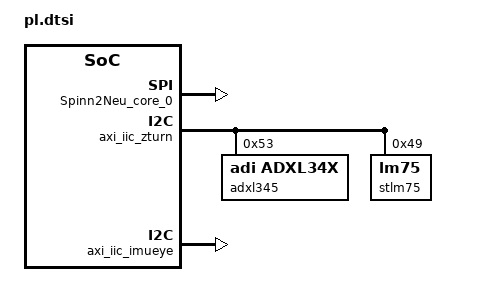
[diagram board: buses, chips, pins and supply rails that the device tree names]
/*
 * CAUTION: This file is automatically generated by Xilinx.
 * Version:  
 * Today is: Mon Jun  4 12:16:58 2018
 */


/ {
	amba_pl: amba_pl {
		#address-cells = <1>;
		#size-cells = <1>;
		compatible = "simple-bus";
		ranges ;
		Spinn2Neu_core_0: Spinn2Neu_core@43c00000 {
			compatible = "iit.it,Spinn2Neu-core-1.0";
			interrupt-parent = <&intc>;
			interrupts = <0 31 4>;
			reg = <0x43c00000 0x10000>;
			xlnx,debug = "false";
			xlnx,dphase-timeout = <0x8>;
			xlnx,num-mem = <0x1>;
			xlnx,num-reg = <0x18>;
			xlnx,s-axi-min-size = <0x000001FF>;
			xlnx,slv-awidth = <0x20>;
			xlnx,slv-dwidth = <0x20>;
			xlnx,use-wstrb = <0x1>;
		};
		axi_dma_0: dma@40400000 {
			#dma-cells = <1>;
			clock-names = "s_axi_lite_aclk", "m_axi_sg_aclk", "m_axi_mm2s_aclk", "m_axi_s2mm_aclk";
			clocks = <&clkc 15>, <&clkc 15>, <&clkc 15>, <&clkc 15>;
			compatible = "xlnx,axi-dma-1.00.a";
			interrupt-parent = <&intc>;
			interrupts = <0 29 4 0 30 4>;
			reg = <0x40400000 0x10000>;
			xlnx,addrwidth = <0x20>;
			dma-channel@40400000 {
				compatible = "xlnx,axi-dma-mm2s-channel";
				dma-channels = <0x1>;
				interrupts = <0 29 4>;
				xlnx,datawidth = <0x20>;
				xlnx,device-id = <0x0>;
			};
			dma-channel@40400030 {
				compatible = "xlnx,axi-dma-s2mm-channel";
				dma-channels = <0x1>;
				interrupts = <0 30 4>;
				xlnx,datawidth = <0x20>;
				xlnx,device-id = <0x0>;
			};
		};
		axi_iic_zturn: i2c@41600000 {
			#address-cells = <1>;
			#size-cells = <0>;
			clock-names = "ref_clk";
			clocks = <&clkc 15>;
			compatible = "xlnx,xps-iic-2.00.a";
			interrupt-parent = <&intc>;
			interrupts = <0 32 4>;
			reg = <0x41600000 0x10000>;
    			adxl345@53 {
            			compatible = "adi,adxl34x", "adxl34x";
            			reg = <0x53>;
            			interrupt-parent = <&intc>;
            			interrupts = <0 33 4>;
    			};
    			stlm75@49 {
            			status = "okay";
            			compatible = "lm75";
            			reg = <0x49>;
            			//interrupt-parent = <&intc>;
            			//interrupts = <0 33 4>;
    			};
		};
		axi_iic_imueye: i2c@41610000 {
			#address-cells = <1>;
			#size-cells = <0>;
			clock-names = "ref_clk";
			clocks = <&clkc 15>;
			compatible = "xlnx,xps-iic-2.00.a";
			interrupt-parent = <&intc>;
			interrupts = <0 34 4>;
			reg = <0x41610000 0x10000>;
		};
	};
};
